AUTOSAR XML (schema 4-0-3)
standard types defined: UInt32, UInt8
package /AUTOSAR_Platform/DataConstrs
  range DC_UInt8: raw 0..255
package /PATAC/MSM/ComponentTypes
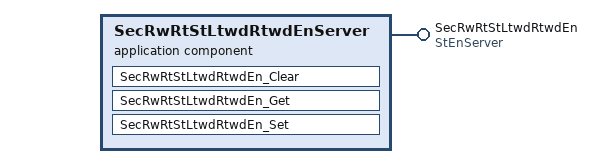
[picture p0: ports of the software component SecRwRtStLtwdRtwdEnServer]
  application sw component type SecRwRtStLtwdRtwdEnServer
    provide port SecRwRtStLtwdRtwdEn: provided-com-specs=[{operation=Clear, queue-length=1}, {operation=Get, queue-length=1}, {operation=Set, queue-length=1}], provided-interface=StEnServer
    behavior SecRwRtStLtwdRtwdEnServer_InternalBehavior
      operation invoked event OIT_SecRwRtStLtwdRtwdEn_Clear_SecRwRtStLtwdRtwdEn_Clear: start-on-event=SecRwRtStLtwdRtwdEn_Clear, operation=SecRwRtStLtwdRtwdEn.Clear
      operation invoked event OIT_SecRwRtStLtwdRtwdEn_Get_SecRwRtStLtwdRtwdEn_Get: start-on-event=SecRwRtStLtwdRtwdEn_Get, operation=SecRwRtStLtwdRtwdEn.Get
      operation invoked event OIT_SecRwRtStLtwdRtwdEn_Set_SecRwRtStLtwdRtwdEn_Set: start-on-event=SecRwRtStLtwdRtwdEn_Set, operation=SecRwRtStLtwdRtwdEn.Set
      runnable SecRwRtStLtwdRtwdEn_Clear
      runnable SecRwRtStLtwdRtwdEn_Get
      runnable SecRwRtStLtwdRtwdEn_Set
  swc implementation SecRwRtStLtwdRtwdEnServer_Implementation: behavior=SecRwRtStLtwdRtwdEnServer_InternalBehavior
    code-descriptors:
      code Default: artifact-descriptors=autosar-engineering-object={short-label=Default, category=SWSRC}
package /PATAC/MSM/ModeAdjust/PortInterface
  client server interface StEnServer
    operation Clear
      arg data: type=UInt8, direction=IN, server-argument-impl-policy=USE-ARGUMENT-TYPE
    operation Get
      arg data: type=UInt32, direction=OUT, server-argument-impl-policy=USE-ARGUMENT-TYPE
    operation Set
      arg data: type=UInt8, direction=IN, server-argument-impl-policy=USE-ARGUMENT-TYPE
